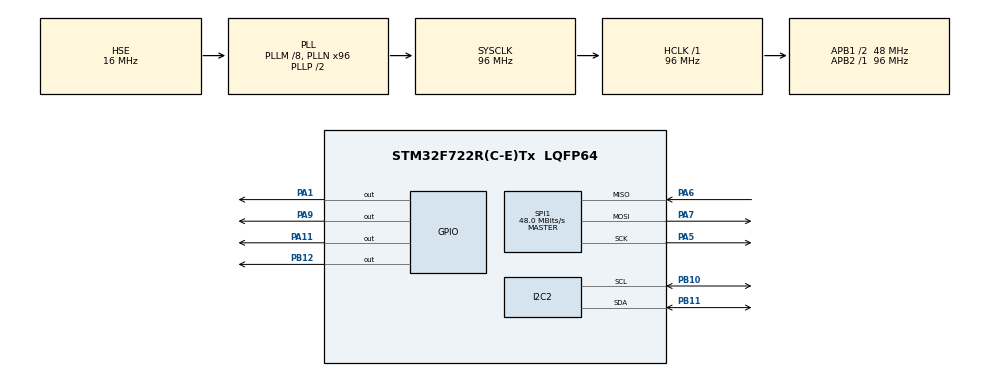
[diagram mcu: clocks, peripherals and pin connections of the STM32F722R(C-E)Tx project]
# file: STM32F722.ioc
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CORTEX_M7.default_mode_Activation=1
I2C2.Timing=0x20303E5D
Mcu.Family=STM32F7
Mcu.Name=STM32F722R(C-E)Tx
Mcu.Package=LQFP64
NVIC.PriorityGroup=NVIC_PRIORITYGROUP_4
PA1.GPIO_ModeDefaultOutputPP=GPIO_MODE_OUTPUT_PP
PA1.Signal=GPIO_Output
PA11.Signal=GPIO_Output
PA13.Mode=Trace_Asynchronous_SW
PA13.Signal=SYS_JTMS-SWDIO
PA14.Mode=Trace_Asynchronous_SW
PA14.Signal=SYS_JTCK-SWCLK
PA5.Mode=Full_Duplex_Master
PA5.Signal=SPI1_SCK
PA6.Mode=Full_Duplex_Master
PA6.Signal=SPI1_MISO
PA7.Mode=Full_Duplex_Master
PA7.Signal=SPI1_MOSI
PA9.Signal=GPIO_Output
PB10.Mode=I2C
PB10.Signal=I2C2_SCL
PB11.Mode=I2C
PB11.Signal=I2C2_SDA
PB12.Signal=GPIO_Output
PB3.Mode=Trace_Asynchronous_SW
PB3.Signal=SYS_JTDO-SWO
PC14-OSC32_IN.Mode=LSE-External-Oscillator
PC14-OSC32_IN.Signal=RCC_OSC32_IN
PC15-OSC32_OUT.Mode=LSE-External-Oscillator
PC15-OSC32_OUT.Signal=RCC_OSC32_OUT
PH0-OSC_IN.Mode=HSE-External-Oscillator
PH0-OSC_IN.Signal=RCC_OSC_IN
PH1-OSC_OUT.Mode=HSE-External-Oscillator
PH1-OSC_OUT.Signal=RCC_OSC_OUT
ProjectManager.HeapSize=0x200
ProjectManager.StackSize=0x400
ProjectManager.TargetToolchain=STM32CubeIDE
RCC.AHBFreq_Value=96000000
RCC.APB1CLKDivider=RCC_HCLK_DIV2
RCC.APB1Freq_Value=48000000
RCC.APB1TimFreq_Value=96000000
RCC.APB2Freq_Value=96000000
RCC.APB2TimFreq_Value=96000000
RCC.CortexFreq_Value=96000000
RCC.HCLKFreq_Value=96000000
RCC.HSE_VALUE=16000000
RCC.HSI_VALUE=16000000
RCC.PLLM=8
RCC.PLLN=96
RCC.PLLSourceVirtual=RCC_PLLSOURCE_HSE
RCC.PWREXT_OverDrive=PWREXT_OverDrive_ACTIVATED
RCC.PWR_Regulator_Voltage_Scale=PWR_REGULATOR_VOLTAGE_SCALE1
RCC.SYSCLKFreq_VALUE=96000000
RCC.SYSCLKSource=RCC_SYSCLKSOURCE_PLLCLK
RCC.USBFreq_Value=96000000
RCC.VCOOutputFreq_Value=192000000
SPI1.BaudRatePrescaler=SPI_BAUDRATEPRESCALER_2
SPI1.CalculateBaudRate=48.0 MBits/s
SPI1.Direction=SPI_DIRECTION_2LINES
SPI1.Mode=SPI_MODE_MASTER
SPI1.VirtualType=VM_MASTER
board=custom

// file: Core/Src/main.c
/* USER CODE BEGIN Header */
/**
  ******************************************************************************
  * @file           : main.c
  * @brief          : Main program body
  ******************************************************************************
  * @attention
  *
  * Copyright (c) 2025 STMicroelectronics.
  * All rights reserved.
  *
  * This software is licensed under terms that can be found in the LICENSE file
  * in the root directory of this software component.
  * If no LICENSE file comes with this software, it is provided AS-IS.
  *
  ******************************************************************************
  */
/* USER CODE END Header */
#include "main.h"

I2C_HandleTypeDef hi2c2;

SPI_HandleTypeDef hspi1;

void SystemClock_Config(void);
static void MPU_Config(void);
static void MX_GPIO_Init(void);
static void MX_I2C2_Init(void);
static void MX_SPI1_Init(void);

int main(void)
{

  /* MPU Configuration--------------------------------------------------------*/
  MPU_Config();

  /* MCU Configuration--------------------------------------------------------*/

  /* Reset of all peripherals, Initializes the Flash interface and the Systick. */
  HAL_Init();

  /* Configure the system clock */
  SystemClock_Config();

  /* Initialize all configured peripherals */
  MX_GPIO_Init();
  MX_I2C2_Init();
  MX_SPI1_Init();

  /* Infinite loop */
  while (1)
  {

    /* USER CODE BEGIN 3 */
	  HAL_GPIO_WritePin(GPIOA, GPIO_PIN_1, GPIO_PIN_SET);
	  HAL_Delay(500);
	  HAL_GPIO_WritePin(GPIOA, GPIO_PIN_1, GPIO_PIN_RESET);
	  HAL_Delay(500);
  }
  /* USER CODE END 3 */
}

void SystemClock_Config(void)
{
  RCC_OscInitTypeDef RCC_OscInitStruct = {0};
  RCC_ClkInitTypeDef RCC_ClkInitStruct = {0};

  /** Configure LSE Drive Capability
  */
  HAL_PWR_EnableBkUpAccess();

  /** Configure the main internal regulator output voltage
  */
  __HAL_RCC_PWR_CLK_ENABLE();
  __HAL_PWR_VOLTAGESCALING_CONFIG(PWR_REGULATOR_VOLTAGE_SCALE1);

  /** Initializes the RCC Oscillators according to the specified parameters
  * in the RCC_OscInitTypeDef structure.
  */
  RCC_OscInitStruct.OscillatorType = RCC_OSCILLATORTYPE_HSE;
  RCC_OscInitStruct.HSEState = RCC_HSE_ON;
  RCC_OscInitStruct.PLL.PLLState = RCC_PLL_ON;
  RCC_OscInitStruct.PLL.PLLSource = RCC_PLLSOURCE_HSE;
  RCC_OscInitStruct.PLL.PLLM = 8;
  RCC_OscInitStruct.PLL.PLLN = 96;
  RCC_OscInitStruct.PLL.PLLP = RCC_PLLP_DIV2;
  RCC_OscInitStruct.PLL.PLLQ = 2;
  if (HAL_RCC_OscConfig(&RCC_OscInitStruct) != HAL_OK)
  {
    Error_Handler();
  }

  /** Activate the Over-Drive mode
  */
  if (HAL_PWREx_EnableOverDrive() != HAL_OK)
  {
    Error_Handler();
  }

  /** Initializes the CPU, AHB and APB buses clocks
  */
  RCC_ClkInitStruct.ClockType = RCC_CLOCKTYPE_HCLK|RCC_CLOCKTYPE_SYSCLK
                              |RCC_CLOCKTYPE_PCLK1|RCC_CLOCKTYPE_PCLK2;
  RCC_ClkInitStruct.SYSCLKSource = RCC_SYSCLKSOURCE_PLLCLK;
  RCC_ClkInitStruct.AHBCLKDivider = RCC_SYSCLK_DIV1;
  RCC_ClkInitStruct.APB1CLKDivider = RCC_HCLK_DIV2;
  RCC_ClkInitStruct.APB2CLKDivider = RCC_HCLK_DIV1;

  if (HAL_RCC_ClockConfig(&RCC_ClkInitStruct, FLASH_LATENCY_3) != HAL_OK)
  {
    Error_Handler();
  }
}

static void MX_I2C2_Init(void)
{

  hi2c2.Instance = I2C2;
  hi2c2.Init.Timing = 0x20303E5D;
  hi2c2.Init.OwnAddress1 = 0;
  hi2c2.Init.AddressingMode = I2C_ADDRESSINGMODE_7BIT;
  hi2c2.Init.DualAddressMode = I2C_DUALADDRESS_DISABLE;
  hi2c2.Init.OwnAddress2 = 0;
  hi2c2.Init.OwnAddress2Masks = I2C_OA2_NOMASK;
  hi2c2.Init.GeneralCallMode = I2C_GENERALCALL_DISABLE;
  hi2c2.Init.NoStretchMode = I2C_NOSTRETCH_DISABLE;
  if (HAL_I2C_Init(&hi2c2) != HAL_OK)
  {
    Error_Handler();
  }

  /** Configure Analogue filter
  */
  if (HAL_I2CEx_ConfigAnalogFilter(&hi2c2, I2C_ANALOGFILTER_ENABLE) != HAL_OK)
  {
    Error_Handler();
  }

  /** Configure Digital filter
  */
  if (HAL_I2CEx_ConfigDigitalFilter(&hi2c2, 0) != HAL_OK)
  {
    Error_Handler();
  }

}

static void MX_SPI1_Init(void)
{

  /* SPI1 parameter configuration*/
  hspi1.Instance = SPI1;
  hspi1.Init.Mode = SPI_MODE_MASTER;
  hspi1.Init.Direction = SPI_DIRECTION_2LINES;
  hspi1.Init.DataSize = SPI_DATASIZE_4BIT;
  hspi1.Init.CLKPolarity = SPI_POLARITY_LOW;
  hspi1.Init.CLKPhase = SPI_PHASE_1EDGE;
  hspi1.Init.NSS = SPI_NSS_SOFT;
  hspi1.Init.BaudRatePrescaler = SPI_BAUDRATEPRESCALER_2;
  hspi1.Init.FirstBit = SPI_FIRSTBIT_MSB;
  hspi1.Init.TIMode = SPI_TIMODE_DISABLE;
  hspi1.Init.CRCCalculation = SPI_CRCCALCULATION_DISABLE;
  hspi1.Init.CRCPolynomial = 7;
  hspi1.Init.CRCLength = SPI_CRC_LENGTH_DATASIZE;
  hspi1.Init.NSSPMode = SPI_NSS_PULSE_ENABLE;
  if (HAL_SPI_Init(&hspi1) != HAL_OK)
  {
    Error_Handler();
  }

}

static void MX_GPIO_Init(void)
{
  GPIO_InitTypeDef GPIO_InitStruct = {0};

  /* GPIO Ports Clock Enable */
  __HAL_RCC_GPIOC_CLK_ENABLE();
  __HAL_RCC_GPIOH_CLK_ENABLE();
  __HAL_RCC_GPIOA_CLK_ENABLE();
  __HAL_RCC_GPIOB_CLK_ENABLE();

  /*Configure GPIO pin Output Level */
  HAL_GPIO_WritePin(GPIOA, GPIO_PIN_1|GPIO_PIN_9|GPIO_PIN_11, GPIO_PIN_RESET);

  /*Configure GPIO pin Output Level */
  HAL_GPIO_WritePin(GPIOB, GPIO_PIN_12, GPIO_PIN_RESET);

  /*Configure GPIO pins : PA1 PA9 PA11 */
  GPIO_InitStruct.Pin = GPIO_PIN_1|GPIO_PIN_9|GPIO_PIN_11;
  GPIO_InitStruct.Mode = GPIO_MODE_OUTPUT_PP;
  GPIO_InitStruct.Pull = GPIO_NOPULL;
  GPIO_InitStruct.Speed = GPIO_SPEED_FREQ_LOW;
  HAL_GPIO_Init(GPIOA, &GPIO_InitStruct);

  /*Configure GPIO pin : PB12 */
  GPIO_InitStruct.Pin = GPIO_PIN_12;
  GPIO_InitStruct.Mode = GPIO_MODE_OUTPUT_PP;
  GPIO_InitStruct.Pull = GPIO_NOPULL;
  GPIO_InitStruct.Speed = GPIO_SPEED_FREQ_LOW;
  HAL_GPIO_Init(GPIOB, &GPIO_InitStruct);

}

 /* MPU Configuration */

void MPU_Config(void)
{
  MPU_Region_InitTypeDef MPU_InitStruct = {0};

  /* Disables the MPU */
  HAL_MPU_Disable();

  /** Initializes and configures the Region and the memory to be protected
  */
  MPU_InitStruct.Enable = MPU_REGION_ENABLE;
  MPU_InitStruct.Number = MPU_REGION_NUMBER0;
  MPU_InitStruct.BaseAddress = 0x0;
  MPU_InitStruct.Size = MPU_REGION_SIZE_4GB;
  MPU_InitStruct.SubRegionDisable = 0x87;
  MPU_InitStruct.TypeExtField = MPU_TEX_LEVEL0;
  MPU_InitStruct.AccessPermission = MPU_REGION_NO_ACCESS;
  MPU_InitStruct.DisableExec = MPU_INSTRUCTION_ACCESS_DISABLE;
  MPU_InitStruct.IsShareable = MPU_ACCESS_SHAREABLE;
  MPU_InitStruct.IsCacheable = MPU_ACCESS_NOT_CACHEABLE;
  MPU_InitStruct.IsBufferable = MPU_ACCESS_NOT_BUFFERABLE;

  HAL_MPU_ConfigRegion(&MPU_InitStruct);
  /* Enables the MPU */
  HAL_MPU_Enable(MPU_PRIVILEGED_DEFAULT);

}

void Error_Handler(void)
{
  __disable_irq();
  while (1)
  {
  }
}
